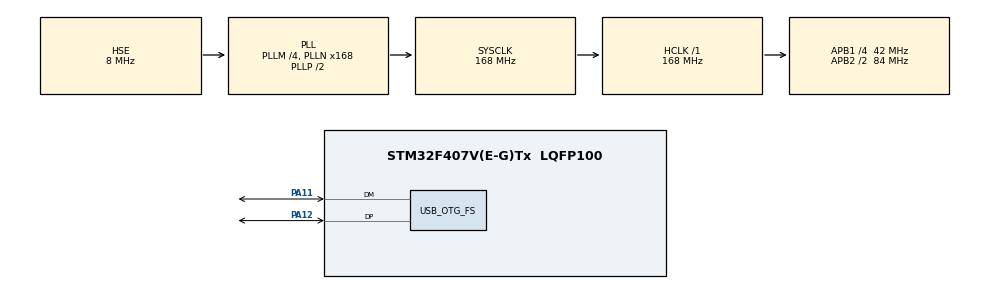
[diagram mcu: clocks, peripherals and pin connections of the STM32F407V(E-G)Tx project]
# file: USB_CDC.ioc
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Mcu.Family=STM32F4
Mcu.Name=STM32F407V(E-G)Tx
Mcu.Package=LQFP100
NVIC.OTG_FS_IRQn=true\:0\:0\:false\:false\:true\:false\:true
NVIC.PriorityGroup=NVIC_PRIORITYGROUP_4
PA11.Mode=Device_Only
PA11.Signal=USB_OTG_FS_DM
PA12.Mode=Device_Only
PA12.Signal=USB_OTG_FS_DP
PH0-OSC_IN.Mode=HSE-External-Oscillator
PH0-OSC_IN.Signal=RCC_OSC_IN
PH1-OSC_OUT.Mode=HSE-External-Oscillator
PH1-OSC_OUT.Signal=RCC_OSC_OUT
ProjectManager.HeapSize=0x200
ProjectManager.StackSize=0x400
ProjectManager.TargetToolchain=MDK-ARM V5
RCC.48MHZClocksFreq_Value=48000000
RCC.AHBFreq_Value=168000000
RCC.APB1CLKDivider=RCC_HCLK_DIV4
RCC.APB1Freq_Value=42000000
RCC.APB1TimFreq_Value=84000000
RCC.APB2CLKDivider=RCC_HCLK_DIV2
RCC.APB2Freq_Value=84000000
RCC.APB2TimFreq_Value=168000000
RCC.CortexFreq_Value=168000000
RCC.HCLKFreq_Value=168000000
RCC.HSE_VALUE=8000000
RCC.HSI_VALUE=16000000
RCC.LSE_VALUE=32768
RCC.PLLM=4
RCC.PLLN=168
RCC.PLLQ=7
RCC.SYSCLKFreq_VALUE=168000000
RCC.SYSCLKSource=RCC_SYSCLKSOURCE_PLLCLK
RCC.VCOOutputFreq_Value=336000000
USB_DEVICE.CLASS_NAME_FS=CDC
USB_DEVICE.VirtualMode-CDC_FS=Cdc
USB_DEVICE.VirtualModeFS=Cdc_FS
USB_OTG_FS.VirtualMode=Device_Only
VP_USB_DEVICE_VS_USB_DEVICE_CDC_FS.Mode=CDC_FS
board=custom

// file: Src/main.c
/* USER CODE BEGIN Header */
/**
  ******************************************************************************
  * @file           : main.c
  * @brief          : Main program body
  ******************************************************************************
  * @attention
  *
  * <h2><center>&copy; Copyright (c) 2019 STMicroelectronics.
  * All rights reserved.</center></h2>
  *
  * This software component is licensed by ST under Ultimate Liberty license
  * SLA0044, the "License"; You may not use this file except in compliance with
  * the License. You may obtain a copy of the License at:
  *                             www.st.com/SLA0044
  *
  ******************************************************************************
  */
/* USER CODE END Header */

#include "main.h"
#include "usb_device.h"
#include "usbd_cdc_if.h"
//#include "sys_usb.h"
#include "fos.h"
#include "tcp.h"
//#include "inet.h"

/* USER CODE BEGIN PV */
char rec_data[64] = {0x00};
//inet_info_connection_t m_info_connection;

/* USER CODE END PV */

void SystemClock_Config(void);
static void MX_GPIO_Init(void);

typedef struct
{
	uint8_t Header;
	uint8_t Type;
	uint8_t Cmd;
	uint8_t Len[2];
	uint8_t Data[1000];
} Packet_T;
uint8_t packet[8];
char arr[] = "ATD";

enum
{
	IDX_HEADER = 0,
	IDX_TYPE   = 1,
	IDX_CMD    = 2,
	IDX_LEN    = 3,
	IDX_DATA   = 5
};

TCP_Data_T tData_Rec[20]= {0x00};
TCP_Status_T mStatus;
int main(void)
{

  /* MCU Configuration--------------------------------------------------------*/

  /* Reset of all peripherals, Initializes the Flash interface and the Systick. */
  HAL_Init();

  /* Configure the system clock */
  SystemClock_Config();

  /* Initialize all configured peripherals */
  MX_GPIO_Init();
	//FOS_Init();
	mStatus = TCP_Init();
	mStatus = TCP_Establish_Connection("127.0.0.2", 9999);
	mStatus = TCP_Send_Data("Linh", 4);
	mStatus = TCP_Receive_Data(rec_data);
	mStatus = TCP_Close_Connection();
	//FOS_Start();

	//inet_init();
	//inet_get_info_connection(&m_info_connection);

  //MX_USB_DEVICE_Init();

//	Packet_T packet;
//		packet.Header = 0x55,
//		packet.Type   = 0x01,
//		memset(packet.Len, 0x01, 2);
//		memcpy(packet.Data, arr, sizeof(arr));
// packet[IDX_HEADER] = 0x55;
// packet[IDX_TYPE] = 0x01;
// packet[IDX_CMD]   = 0x00;
// packet[IDX_LEN] = 0x00;
// packet[IDX_LEN + 1] = 0x03;
// memcpy(&packet[IDX_DATA], arr, 3);

// 	HAL_Delay(10000);
// 	CDC_Transmit_FS(packet, 8);
// 	HAL_Delay(1);
// 	packet[IDX_CMD]   = 0x01;
// 	CDC_Transmit_FS(packet, 8);
// 	HAL_Delay(1);
// 	packet[IDX_CMD]   = 0x02;
// 	CDC_Transmit_FS(packet, 8);
// 	HAL_Delay(1);
// 	packet[IDX_CMD]   = 0x03;
// 	CDC_Transmit_FS(packet, 8);
// 	HAL_Delay(1);
// 	packet[IDX_CMD]   = 0x04;
// 	CDC_Transmit_FS(packet, 8);

  /* Infinite loop */
  while (1)
  {
		//FOS_Run();

    /* USER CODE BEGIN 3 */
//		CDC_Transmit_FS((uint8_t *) "Hello world\n", sizeof("Hello world\n"));

  }
  /* USER CODE END 3 */
}

void SystemClock_Config(void)
{
  RCC_OscInitTypeDef RCC_OscInitStruct = {0};
  RCC_ClkInitTypeDef RCC_ClkInitStruct = {0};

  /** Configure the main internal regulator output voltage
  */
  __HAL_RCC_PWR_CLK_ENABLE();
  __HAL_PWR_VOLTAGESCALING_CONFIG(PWR_REGULATOR_VOLTAGE_SCALE1);
  /** Initializes the CPU, AHB and APB busses clocks
  */
  RCC_OscInitStruct.OscillatorType = RCC_OSCILLATORTYPE_HSE;
  RCC_OscInitStruct.HSEState = RCC_HSE_ON;
  RCC_OscInitStruct.PLL.PLLState = RCC_PLL_ON;
  RCC_OscInitStruct.PLL.PLLSource = RCC_PLLSOURCE_HSE;
  RCC_OscInitStruct.PLL.PLLM = 4;
  RCC_OscInitStruct.PLL.PLLN = 168;
  RCC_OscInitStruct.PLL.PLLP = RCC_PLLP_DIV2;
  RCC_OscInitStruct.PLL.PLLQ = 7;
  if (HAL_RCC_OscConfig(&RCC_OscInitStruct) != HAL_OK)
  {
    Error_Handler();
  }
  /** Initializes the CPU, AHB and APB busses clocks
  */
  RCC_ClkInitStruct.ClockType = RCC_CLOCKTYPE_HCLK|RCC_CLOCKTYPE_SYSCLK
                              |RCC_CLOCKTYPE_PCLK1|RCC_CLOCKTYPE_PCLK2;
  RCC_ClkInitStruct.SYSCLKSource = RCC_SYSCLKSOURCE_PLLCLK;
  RCC_ClkInitStruct.AHBCLKDivider = RCC_SYSCLK_DIV1;
  RCC_ClkInitStruct.APB1CLKDivider = RCC_HCLK_DIV4;
  RCC_ClkInitStruct.APB2CLKDivider = RCC_HCLK_DIV2;

  if (HAL_RCC_ClockConfig(&RCC_ClkInitStruct, FLASH_LATENCY_5) != HAL_OK)
  {
    Error_Handler();
  }
}

static void MX_GPIO_Init(void)
{

  /* GPIO Ports Clock Enable */
  __HAL_RCC_GPIOH_CLK_ENABLE();
  __HAL_RCC_GPIOA_CLK_ENABLE();

}

void Error_Handler(void)
{
}

/************************ (C) COPYRIGHT STMicroelectronics *****END OF FILE****/
